# AM13E230x register map
Vendor: Texas Instruments; File version: Revised: 2025-12-26 17:30:06
CPU: CM33 r0p0, little endian, MPU, FPU, 4 interrupt priority bits
Registers are 32-bit, read-write, reset 0x0 unless marked. A register's access mark holds for its fields unless they carry their own. Offsets are from the block's base; [hi:lo] are bit positions; lines under a group give offsets from that group; {n}, {i} and the like mark numbered series.

## CRCP — PERIPHERALREGION
Base 0x401B2000
{0x800+0x18*i} GPRCM[{i}] (i=0..0) group
  0x00 PWREN — Power enable
    [0] ENABLE — Power Enable
      0=DISABLE (Disable Power); 1=ENABLE (Enable Power)
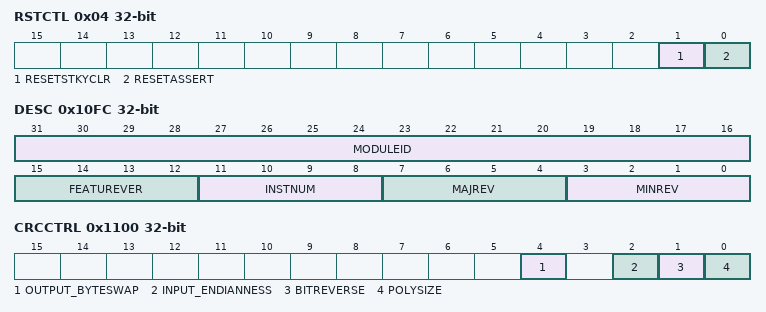
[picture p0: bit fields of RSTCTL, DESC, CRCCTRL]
  0x04 RSTCTL wo — Reset Control
    [1] RESETSTKYCLR — Reset sticky bit clear
      0=NOP (Writing 0 has no effect); 1=CLR (Clear reset sticky bit)
    [0] RESETASSERT — Reset assertion to the peripheral
      0=NOP (Writing 0 has no effect); 1=ASSERT (Assert reset)
  0x14 STAT ro — Status Register
    [16] RESETSTKY — Reset sticky bit
      0=NORES (The peripheral has not been reset since this bit was last cleared by RESETSTKYCLR in the RSTCTL register); 1=RESET (The peripheral was reset since the last bit clear)
0x1004 CLKSEL ro reset 0x1 — Clock Select
  [0] MCLK_SEL — Selects main clock (MCLK) if enabled
    0=DISABLE (Does not select this clock as a source); 1=ENABLE (Select this clock as a source)
0x10FC DESC ro — Module Description
  [31:16] MODULEID — Module identification contains a unique peripheral identification number. The assignments are maintained in a central database for all of the platform modules to ensure uniqueness.
  [15:12] FEATUREVER — Feature Set for the module *instance*
  [11:8] INSTNUM — Instance Number within the device. This will be a parameter to the RTL for modules that can have multiple instances
  [7:4] MAJREV — Major rev of the IP
  [3:0] MINREV — Minor rev of the IP
0x1100 CRCCTRL (reset mask 0x7) — CRC Control Register
  [4] OUTPUT_BYTESWAP — CRC Output Byteswap Enable. This bit controls whether the output is byte-swapped upon a read of the CRCOUT register. If CRCOUT is accessed as a half-word, and the OUTPUT_BYTESWAP is set to to 1, then the two bytes in the 16-bit access are swapped and returned. B1 is returned as B0 B0 is returned as B1 If CRCOUT is accessed as a word, and the OUTPUT_BYTESWAP is set to 1, then the four bytes in the 32-bit read are swapped. B3 is returned as B0 B2 is returned as B1 B1 is returned as B2 B0 is returned as B3 Note that if the CRC POLYSIZE is 16-bit and a 32-bit read of CRCOUT is performed with OUTPUT_BYTESWAP enabled, then the output is: MSB LSB 0x0 0x0 B0 B1 If the CRC POLYSIZE is 16-bit and a 32-bit read of CRCOUT is performed with OUTPUT_BYTESWAP disabled, then the output is: MSB LSB 0x0 0x0 B1 B0
    0=DISABLE (Output byteswapping is disabled); 1=ENABLE (Output byteswapping is enabled.)
  [2] INPUT_ENDIANNESS — CRC Endian. This bit indicates the byte order within a word or half word of input data.
    0=LITTLE_ENDIAN (LSB is lowest memory address and first to be processed.); 1=BIG_ENDIAN (LSB is highest memory address and last to be processed.)
  [1] BITREVERSE — CRC Bit Input and output Reverse. This bit indictes that the bit order of each input byte used for the CRC calculation is reversed before it is passed to the generator, and that the bit order of the calculated CRC is be reversed when read from CRC_RESULT.
    0=NOT_REVERSED (Bit order is not reversed.); 1=REVERSED (Bit order is reversed.)
  [0] POLYSIZE — This bit indicates which CRC calculation is performed by the generator.
    0=CRC32 (CRC-32 ISO-3309 calulation is performed); 1=CRC16 (CRC-16 CCITT is performed)
0x1104 CRCSEED wo
  [31:0] SEED — Seed Data
0x1108 CRCIN wo — CRC Input Data Register
  [31:0] DATA — Input Data
0x110C CRCOUT ro — CRC Output Result Register
  [31:0] RESULT
0x1110 CRCPOLY — CRC Polynomial configuration register
{0x1800+4i} CRCIN_IDX[{i}] (i=0..511) wo — CRC Input Data Array Register
  [31:0] DATA — Input Data

## EAM — EAM_REGS
Base 0x4002C000
0x1000 REVISION — IP revision id register
  [0] REVISION ro
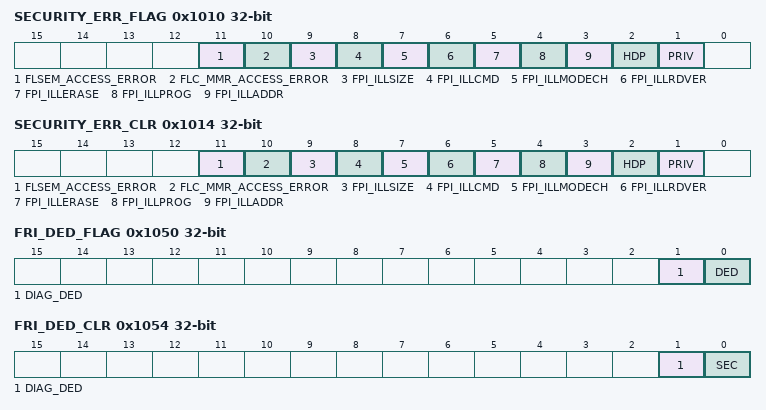
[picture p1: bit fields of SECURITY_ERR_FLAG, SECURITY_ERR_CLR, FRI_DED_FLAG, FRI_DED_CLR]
0x1010 SECURITY_ERR_FLAG — Security error flag
  [11] FLSEM_ACCESS_ERROR ro
  [10] FLC_MMR_ACCESS_ERROR ro
  [9] FPI_ILLSIZE ro
  [8] FPI_ILLCMD ro
  [7] FPI_ILLMODECH ro
  [6] FPI_ILLRDVER ro
  [5] FPI_ILLERASE ro
  [4] FPI_ILLPROG ro
  [3] FPI_ILLADDR ro
  [2] HDP ro — Hide protection error
  [1] PRIV ro — Privilege error
0x1014 SECURITY_ERR_CLR — Security error clear
  [11] FLSEM_ACCESS_ERROR
  [10] FLC_MMR_ACCESS_ERROR
  [9] FPI_ILLSIZE
  [8] FPI_ILLCMD
  [7] FPI_ILLMODECH
  [6] FPI_ILLRDVER
  [5] FPI_ILLERASE
  [4] FPI_ILLPROG
  [3] FPI_ILLADDR
  [2] HDP — Hide protection error
  [1] PRIV — Privilege error
0x1018 SECURITY_ERR_MSTID — Security error master id
  [7:0] MSTID ro — Master ID
0x101C SECURITY_ERR_ADDR — Security error address
0x1030 FRI_SEC_FLAG
  [0] SEC ro — Single error correction error
0x1034 FRI_SEC_CLR — FRI SEC clear
  [0] SEC — Single error correction error
0x1038 FRI_SEC_ADDR — FRI SEC address
0x103C FRI_SEC_MSTID — FRI SEC master id
  [7:0] MSTID ro — Master ID
0x1050 FRI_DED_FLAG
  [1] DIAG_DED ro — diagnostic Double error detect error
  [0] DED ro — Double error detect error
0x1054 FRI_DED_CLR — FRI DED clear
  [1] DIAG_DED — diagnostic Double error detect error
  [0] SEC — Double error detect error
0x1058 FRI_DED_ADDR — FRI DED address
0x105C FRI_DED_MSTID — FRI DED master id
  [7:0] MSTID ro — Master ID
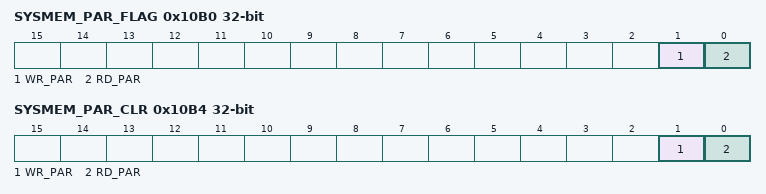
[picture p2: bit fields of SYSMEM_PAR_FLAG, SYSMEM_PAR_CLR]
0x10B0 SYSMEM_PAR_FLAG — SYSMEM DED flag
  [1] WR_PAR ro — diagnostic Double error detect error during write
  [0] RD_PAR ro — Double error detect error during read
0x10B4 SYSMEM_PAR_CLR — SYSMEM DED clear
  [1] WR_PAR — diagnostic Double error detect error
  [0] RD_PAR — Double error detect error
0x10B8 SYSMEM_PAR_ADDR — SYSMEM DED address
0x10BC SYSMEM_PAR_MSTID — SYSMEM DED master id
  [7:0] MSTID ro — Master ID
0x10D0 TMUROM_PAR_FLAG — SYSMEM DED flag
  [0] PAR ro — Double error detect error during read
0x10D4 TMUROM_PAR_CLR — SYSMEM DED clear
  [0] PAR — Double error detect error
0x10D8 TMUROM_PAR_ADDR — SYSMEM DED address
  [14:0] ADDRESS ro
0x10DC TMUROM_PAR_TYPE — SYSMEM DED master id
  [2:0] TYPE ro — Master ID
0x10F0 SYSMEM_ACC_FLAG — SYSMEM access error flag
  [0] ERR ro
0x10F4 SYSMEM_ACC_CLR — SYSMEM access error clear
  [0] ERR — writing '1' will clear SYSMEM_ACC_FLAG[ERR] register.
0x10F8 SYSMEM_ACC_ADDR — SYSMEM access error address
0x10FC SYSMEM_ACC_TYPE — SYSMEM access error type
  [4:0] TYPE ro — Access error type. This field will be cleared along with the corresponding flag clear. [4] - CBUS Access Error [3] - SBUS Access Error [2] - Write Error [1] - Read Error [0] - Fetch Error
